# ATA5702M322 device description
Architecture: AVR8; Family: megaAVR
Registers are 8-bit, access not given, no defined reset value unless marked. A register's access mark holds for its fields unless they carry their own. Offsets are from the block's base; [hi:lo] are bit positions; {n}, {i} and the like mark numbered series.

## LF_TRANSPONDER
Instances: LF_TRANSPONDER 0x00
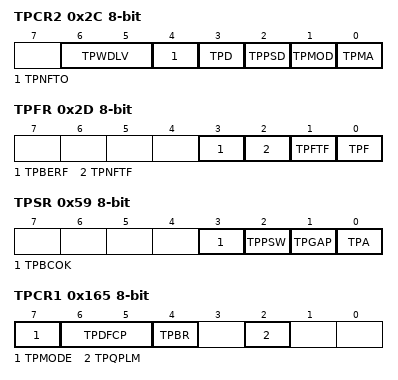
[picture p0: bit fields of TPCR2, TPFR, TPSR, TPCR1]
0x2C TPCR2 — Transponder Control 2 Register
  [6:5] TPWDLV — Transponder watch dog value for No Field timeout (with SRC clk)
    0=1.024 ms; 1=2.048 ms; 2=3.072 ms; 3=4.096 ms
  [4] TPNFTO — Transponder No Field Timeout enable
  [3] TPD — Transponder Disable
  [2] TPPSD — Transponder Power Switch Disable
  [1] TPMOD — Transponder Modulation
  [0] TPMA — Transponder Mode Acknowledge
0x2D TPFR — Transponder Flag Register
  [3] TPBERF — Transponder Bit Error Flag
  [2] TPNFTF — Transponder No Field Timeout Flag
  [1] TPFTF — Transponder Field Timeout Flag
  [0] TPF — Transponder Flag
0x59 TPSR — Transponder Status Register
  [3] TPBCOK — Transponder Battery Charge OK
  [2] TPPSW — Transponder Power Switch
  [1] TPGAP — Transponder GAP Signal
  [0] TPA — Transponder Active
0x165 TPCR1 — Transponder Control Register 1
  [7] TPMODE — Transponder Mode
  [6:5] TPDFCP — Transponder Decoder Field Clock Prescaler value
    0=Field Clock / 1; 1=Field Clock / 1; 2=Field Clock / 2; 3=Field Clock / 4
  [4] TPBR — Transponder Bit Rate
  [2] TPQPLM — Transponder Quadrature Pulse Length Operation Modulation
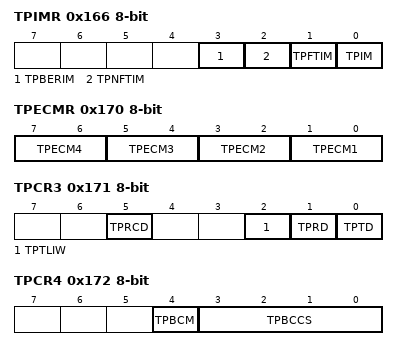
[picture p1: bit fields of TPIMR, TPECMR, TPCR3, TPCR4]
0x166 TPIMR — Transponder Interrupt Mask Register
  [3] TPBERIM — Transponder Bit Error Interrupt Mask
  [2] TPNFTIM — Transponder No Field Timeout Interrupt Mask
  [1] TPFTIM — Transponder Field Timeout Interrupt Mask
  [0] TPIM — Transponder Interrupt Mask
{0x166+i} TPDCR{i} (i=1..5) — Transponder Decoder Comparator Register {i}
  [5:0] TPDCL{i} — Transponder Decode Comparator Length value {i}
{0x16B+i} TPECR{i} (i=1..4) — Transponder Encoder Comparator Register {i}
  [7:0] TPECL{i} — Transponder Encode Comparator Length value {i}
0x170 TPECMR — Transponder Encoder Mode Register
  [all] fields
    0=Manchester; 1=Biphase; 2=NRZ; 3=Manchester
  [2n-1:2n-2] TPECM{n} (n=1..4) — Transponder Encoder Mode {n}
0x171 TPCR3 — Transponder Control Register 3
  [5] TPRCD — Transponder Reception Continuous Damping
  [2] TPTLIW — Transponder Transmit Listen Window
  [1] TPRD — Transponder Receive Data
  [0] TPTD — Transponder Transmit Data
0x172 TPCR4 — Transponder Control Register 4
  [4] TPBCM — Transponder Battery Charge Mode
  [3:0] TPBCCS — Transponder Battery Charge Current Select
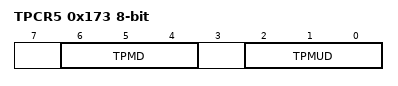
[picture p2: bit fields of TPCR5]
0x173 TPCR5 — Transponder Control Register 5
  [6:4] TPMD — Transponder Modulation Damping Select
  [2:0] TPMUD — Transponder Modulation Undamped Level Select
    0=5.0 V; 1=5.4 V; 2=5.8 V; 3=6.2 V; 4=6.6 V; 5=7.0 V; 7=Up to OVP

## MEM
Instances: MEM 0x00
0x15A PGMST — Program Memory Status Register
  [4:0] PGMSYN — Program Memory Syndrome
0x15B EEST — EEPROM Status Register
  [3:0] EESYN — EEPROM Syndrome

## PORTB
Instances: PORTB 0x00
0x23 PINB — Port B Input Pins
0x24 DDRB — Port B Data Direction Register
0x25 PORTB — Port B Data Register

## PORTC
Instances: PORTC 0x00
0x26 PINC bits used 2:0 — Port C Input Pins
0x27 DDRC bits used 2:0 — Port C Data Direction Register
0x28 PORTC bits used 2:0 — Port C Data Register

## PORTD
Instances: PORTD 0x00
0x29 PIND — Port D Input Pins
0x2A DDRD — Port D Data Direction Register
0x2B PORTD — Port D Data Register

## SFIFO
Instances: SFIFO 0x00
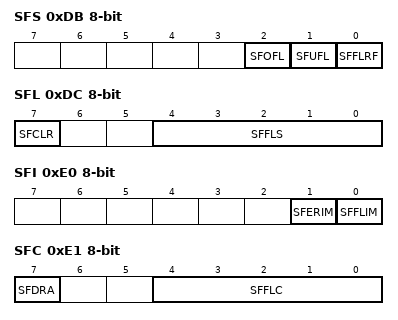
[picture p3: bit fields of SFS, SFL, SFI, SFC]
0xDB SFS — Support FIFO Status Register
  [2] SFOFL — Support FIFO Overflow Flag
  [1] SFUFL — Support FIFO Underflow Flag
  [0] SFFLRF — Support FIFO Fill-Level Reached Status Flag
0xDC SFL — Support FIFO Fill Level Register
  [7] SFCLR — Support FIFO Clear
  [4:0] SFFLS — Support FIFO Fill Level Status
0xDD SFWP bits used 4:0 — Support FIFO Write Pointer
0xDE SFRP bits used 4:0 — Support FIFO Read Pointer
0xDF SFD — Support FIFO Data Register
0xE0 SFI — Support FIFO Interrupt Mask Register
  [1] SFERIM — Support FIFO Error Interrupt Mask
  [0] SFFLIM — Support FIFO Fill-level Interrupt Mask
0xE1 SFC — Support FIFO Configuration Register
  [7] SFDRA — Support FIFO Direct Read Access Operational Mode
  [4:0] SFFLC — Support FIFO Fill-Level Configuration
